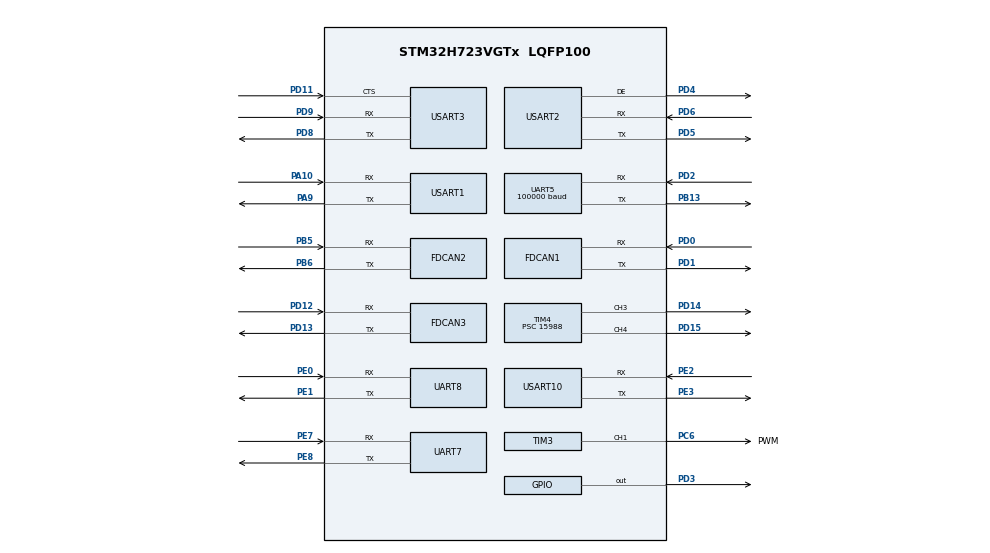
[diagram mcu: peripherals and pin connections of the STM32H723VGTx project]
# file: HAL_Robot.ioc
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Dma.Request0=TIM3_CH1
Dma.Request1=UART7_RX
Dma.Request10=USART1_TX
Dma.Request11=USART3_RX
Dma.Request12=USART3_TX
Dma.Request2=UART7_TX
Dma.Request3=UART8_RX
Dma.Request4=UART8_TX
Dma.Request5=USART10_RX
Dma.Request6=USART10_TX
Dma.Request7=UART5_RX
Dma.Request8=UART5_TX
Dma.Request9=USART1_RX
Dma.TIM3_CH1.0.Direction=DMA_MEMORY_TO_PERIPH
Dma.TIM3_CH1.0.EventEnable=DISABLE
Dma.TIM3_CH1.0.FIFOMode=DMA_FIFOMODE_DISABLE
Dma.TIM3_CH1.0.Instance=DMA1_Stream6
Dma.TIM3_CH1.0.MemDataAlignment=DMA_MDATAALIGN_HALFWORD
Dma.TIM3_CH1.0.MemInc=DMA_MINC_ENABLE
Dma.TIM3_CH1.0.Mode=DMA_NORMAL
Dma.TIM3_CH1.0.PeriphDataAlignment=DMA_PDATAALIGN_HALFWORD
Dma.TIM3_CH1.0.PeriphInc=DMA_PINC_DISABLE
Dma.TIM3_CH1.0.Polarity=HAL_DMAMUX_REQ_GEN_RISING
Dma.TIM3_CH1.0.Priority=DMA_PRIORITY_VERY_HIGH
Dma.TIM3_CH1.0.RequestNumber=1
Dma.TIM3_CH1.0.SignalID=NONE
Dma.TIM3_CH1.0.SyncEnable=DISABLE
Dma.TIM3_CH1.0.SyncPolarity=HAL_DMAMUX_SYNC_NO_EVENT
Dma.TIM3_CH1.0.SyncRequestNumber=1
Dma.TIM3_CH1.0.SyncSignalID=NONE
Dma.UART5_RX.7.Direction=DMA_PERIPH_TO_MEMORY
Dma.UART5_RX.7.EventEnable=DISABLE
Dma.UART5_RX.7.FIFOMode=DMA_FIFOMODE_DISABLE
Dma.UART5_RX.7.Instance=DMA2_Stream2
Dma.UART5_RX.7.MemDataAlignment=DMA_MDATAALIGN_BYTE
Dma.UART5_RX.7.MemInc=DMA_MINC_ENABLE
Dma.UART5_RX.7.Mode=DMA_CIRCULAR
Dma.UART5_RX.7.PeriphDataAlignment=DMA_PDATAALIGN_BYTE
Dma.UART5_RX.7.PeriphInc=DMA_PINC_DISABLE
Dma.UART5_RX.7.Polarity=HAL_DMAMUX_REQ_GEN_RISING
Dma.UART5_RX.7.Priority=DMA_PRIORITY_VERY_HIGH
Dma.UART5_RX.7.RequestNumber=1
Dma.UART5_RX.7.SignalID=NONE
Dma.UART5_RX.7.SyncEnable=DISABLE
Dma.UART5_RX.7.SyncPolarity=HAL_DMAMUX_SYNC_NO_EVENT
Dma.UART5_RX.7.SyncRequestNumber=1
Dma.UART5_RX.7.SyncSignalID=NONE
Dma.UART5_TX.8.Direction=DMA_MEMORY_TO_PERIPH
Dma.UART5_TX.8.EventEnable=DISABLE
Dma.UART5_TX.8.FIFOMode=DMA_FIFOMODE_DISABLE
Dma.UART5_TX.8.Instance=DMA2_Stream3
Dma.UART5_TX.8.MemDataAlignment=DMA_MDATAALIGN_BYTE
Dma.UART5_TX.8.MemInc=DMA_MINC_ENABLE
Dma.UART5_TX.8.Mode=DMA_CIRCULAR
Dma.UART5_TX.8.PeriphDataAlignment=DMA_PDATAALIGN_BYTE
Dma.UART5_TX.8.PeriphInc=DMA_PINC_DISABLE
Dma.UART5_TX.8.Polarity=HAL_DMAMUX_REQ_GEN_RISING
Dma.UART5_TX.8.Priority=DMA_PRIORITY_VERY_HIGH
Dma.UART5_TX.8.RequestNumber=1
Dma.UART5_TX.8.SignalID=NONE
Dma.UART5_TX.8.SyncEnable=DISABLE
Dma.UART5_TX.8.SyncPolarity=HAL_DMAMUX_SYNC_NO_EVENT
Dma.UART5_TX.8.SyncRequestNumber=1
Dma.UART5_TX.8.SyncSignalID=NONE
Dma.UART7_RX.1.Direction=DMA_PERIPH_TO_MEMORY
Dma.UART7_RX.1.EventEnable=DISABLE
Dma.UART7_RX.1.FIFOMode=DMA_FIFOMODE_DISABLE
Dma.UART7_RX.1.Instance=DMA1_Stream4
Dma.UART7_RX.1.MemDataAlignment=DMA_MDATAALIGN_BYTE
Dma.UART7_RX.1.MemInc=DMA_MINC_ENABLE
Dma.UART7_RX.1.Mode=DMA_CIRCULAR
Dma.UART7_RX.1.PeriphDataAlignment=DMA_PDATAALIGN_BYTE
Dma.UART7_RX.1.PeriphInc=DMA_PINC_DISABLE
Dma.UART7_RX.1.Polarity=HAL_DMAMUX_REQ_GEN_RISING
Dma.UART7_RX.1.Priority=DMA_PRIORITY_VERY_HIGH
Dma.UART7_RX.1.RequestNumber=1
Dma.UART7_RX.1.SignalID=NONE
Dma.UART7_RX.1.SyncEnable=DISABLE
Dma.UART7_RX.1.SyncPolarity=HAL_DMAMUX_SYNC_NO_EVENT
Dma.UART7_RX.1.SyncRequestNumber=1
Dma.UART7_RX.1.SyncSignalID=NONE
Dma.UART7_TX.2.Direction=DMA_MEMORY_TO_PERIPH
Dma.UART7_TX.2.EventEnable=DISABLE
Dma.UART7_TX.2.FIFOMode=DMA_FIFOMODE_DISABLE
Dma.UART7_TX.2.Instance=DMA1_Stream5
Dma.UART7_TX.2.MemDataAlignment=DMA_MDATAALIGN_BYTE
Dma.UART7_TX.2.MemInc=DMA_MINC_ENABLE
Dma.UART7_TX.2.Mode=DMA_NORMAL
Dma.UART7_TX.2.PeriphDataAlignment=DMA_PDATAALIGN_BYTE
Dma.UART7_TX.2.PeriphInc=DMA_PINC_DISABLE
Dma.UART7_TX.2.Polarity=HAL_DMAMUX_REQ_GEN_RISING
Dma.UART7_TX.2.Priority=DMA_PRIORITY_VERY_HIGH
Dma.UART7_TX.2.RequestNumber=1
Dma.UART7_TX.2.SignalID=NONE
Dma.UART7_TX.2.SyncEnable=DISABLE
Dma.UART7_TX.2.SyncPolarity=HAL_DMAMUX_SYNC_NO_EVENT
Dma.UART7_TX.2.SyncRequestNumber=1
Dma.UART7_TX.2.SyncSignalID=NONE
Dma.UART8_RX.3.Direction=DMA_PERIPH_TO_MEMORY
Dma.UART8_RX.3.EventEnable=DISABLE
Dma.UART8_RX.3.FIFOMode=DMA_FIFOMODE_DISABLE
Dma.UART8_RX.3.Instance=DMA1_Stream0
Dma.UART8_RX.3.MemDataAlignment=DMA_MDATAALIGN_BYTE
Dma.UART8_RX.3.MemInc=DMA_MINC_ENABLE
Dma.UART8_RX.3.Mode=DMA_CIRCULAR
Dma.UART8_RX.3.PeriphDataAlignment=DMA_PDATAALIGN_BYTE
Dma.UART8_RX.3.PeriphInc=DMA_PINC_DISABLE
Dma.UART8_RX.3.Polarity=HAL_DMAMUX_REQ_GEN_RISING
Dma.UART8_RX.3.Priority=DMA_PRIORITY_LOW
Dma.UART8_RX.3.RequestNumber=1
Dma.UART8_RX.3.SignalID=NONE
Dma.UART8_RX.3.SyncEnable=DISABLE
Dma.UART8_RX.3.SyncPolarity=HAL_DMAMUX_SYNC_NO_EVENT
Dma.UART8_RX.3.SyncRequestNumber=1
Dma.UART8_RX.3.SyncSignalID=NONE
Dma.UART8_TX.4.Direction=DMA_MEMORY_TO_PERIPH
Dma.UART8_TX.4.EventEnable=DISABLE
Dma.UART8_TX.4.FIFOMode=DMA_FIFOMODE_DISABLE
Dma.UART8_TX.4.Instance=DMA1_Stream3
Dma.UART8_TX.4.MemDataAlignment=DMA_MDATAALIGN_BYTE
Dma.UART8_TX.4.MemInc=DMA_MINC_ENABLE
Dma.UART8_TX.4.Mode=DMA_NORMAL
Dma.UART8_TX.4.PeriphDataAlignment=DMA_PDATAALIGN_BYTE
Dma.UART8_TX.4.PeriphInc=DMA_PINC_DISABLE
Dma.UART8_TX.4.Polarity=HAL_DMAMUX_REQ_GEN_RISING
Dma.UART8_TX.4.Priority=DMA_PRIORITY_LOW
Dma.UART8_TX.4.RequestNumber=1
Dma.UART8_TX.4.SignalID=NONE
Dma.UART8_TX.4.SyncEnable=DISABLE
Dma.UART8_TX.4.SyncPolarity=HAL_DMAMUX_SYNC_NO_EVENT
Dma.UART8_TX.4.SyncRequestNumber=1
Dma.UART8_TX.4.SyncSignalID=NONE
Dma.USART10_RX.5.Direction=DMA_PERIPH_TO_MEMORY
Dma.USART10_RX.5.EventEnable=DISABLE
Dma.USART10_RX.5.FIFOMode=DMA_FIFOMODE_DISABLE
Dma.USART10_RX.5.Instance=DMA1_Stream1
Dma.USART10_RX.5.MemDataAlignment=DMA_MDATAALIGN_BYTE
Dma.USART10_RX.5.MemInc=DMA_MINC_ENABLE
Dma.USART10_RX.5.Mode=DMA_CIRCULAR
Dma.USART10_RX.5.PeriphDataAlignment=DMA_PDATAALIGN_BYTE
Dma.USART10_RX.5.PeriphInc=DMA_PINC_DISABLE
Dma.USART10_RX.5.Polarity=HAL_DMAMUX_REQ_GEN_RISING
Dma.USART10_RX.5.Priority=DMA_PRIORITY_VERY_HIGH
Dma.USART10_RX.5.RequestNumber=1
Dma.USART10_RX.5.SignalID=NONE
Dma.USART10_RX.5.SyncEnable=DISABLE
Dma.USART10_RX.5.SyncPolarity=HAL_DMAMUX_SYNC_NO_EVENT
Dma.USART10_RX.5.SyncRequestNumber=1
Dma.USART10_RX.5.SyncSignalID=NONE
Dma.USART10_TX.6.Direction=DMA_MEMORY_TO_PERIPH
Dma.USART10_TX.6.EventEnable=DISABLE
Dma.USART10_TX.6.FIFOMode=DMA_FIFOMODE_DISABLE
Dma.USART10_TX.6.Instance=DMA1_Stream2
Dma.USART10_TX.6.MemDataAlignment=DMA_MDATAALIGN_BYTE
Dma.USART10_TX.6.MemInc=DMA_MINC_ENABLE
Dma.USART10_TX.6.Mode=DMA_CIRCULAR
Dma.USART10_TX.6.PeriphDataAlignment=DMA_PDATAALIGN_BYTE
Dma.USART10_TX.6.PeriphInc=DMA_PINC_DISABLE
Dma.USART10_TX.6.Polarity=HAL_DMAMUX_REQ_GEN_RISING
Dma.USART10_TX.6.Priority=DMA_PRIORITY_VERY_HIGH
Dma.USART10_TX.6.RequestNumber=1
Dma.USART10_TX.6.SignalID=NONE
Dma.USART10_TX.6.SyncEnable=DISABLE
Dma.USART10_TX.6.SyncPolarity=HAL_DMAMUX_SYNC_NO_EVENT
Dma.USART10_TX.6.SyncRequestNumber=1
Dma.USART10_TX.6.SyncSignalID=NONE
Dma.USART1_RX.9.Direction=DMA_PERIPH_TO_MEMORY
Dma.USART1_RX.9.EventEnable=DISABLE
Dma.USART1_RX.9.FIFOMode=DMA_FIFOMODE_DISABLE
Dma.USART1_RX.9.Instance=DMA1_Stream7
Dma.USART1_RX.9.MemDataAlignment=DMA_MDATAALIGN_BYTE
Dma.USART1_RX.9.MemInc=DMA_MINC_ENABLE
Dma.USART1_RX.9.Mode=DMA_CIRCULAR
Dma.USART1_RX.9.PeriphDataAlignment=DMA_PDATAALIGN_BYTE
Dma.USART1_RX.9.PeriphInc=DMA_PINC_DISABLE
Dma.USART1_RX.9.Polarity=HAL_DMAMUX_REQ_GEN_RISING
Dma.USART1_RX.9.Priority=DMA_PRIORITY_VERY_HIGH
Dma.USART1_RX.9.RequestNumber=1
Dma.USART1_RX.9.SignalID=NONE
Dma.USART1_RX.9.SyncEnable=DISABLE
Dma.USART1_RX.9.SyncPolarity=HAL_DMAMUX_SYNC_NO_EVENT
Dma.USART1_RX.9.SyncRequestNumber=1
Dma.USART1_RX.9.SyncSignalID=NONE
Dma.USART1_TX.10.Direction=DMA_MEMORY_TO_PERIPH
Dma.USART1_TX.10.EventEnable=DISABLE
Dma.USART1_TX.10.FIFOMode=DMA_FIFOMODE_DISABLE
Dma.USART1_TX.10.Instance=DMA2_Stream4
Dma.USART1_TX.10.MemDataAlignment=DMA_MDATAALIGN_BYTE
Dma.USART1_TX.10.MemInc=DMA_MINC_ENABLE
Dma.USART1_TX.10.Mode=DMA_CIRCULAR
Dma.USART1_TX.10.PeriphDataAlignment=DMA_PDATAALIGN_BYTE
Dma.USART1_TX.10.PeriphInc=DMA_PINC_DISABLE
Dma.USART1_TX.10.Polarity=HAL_DMAMUX_REQ_GEN_RISING
Dma.USART1_TX.10.Priority=DMA_PRIORITY_VERY_HIGH
Dma.USART1_TX.10.RequestNumber=1
Dma.USART1_TX.10.SignalID=NONE
Dma.USART1_TX.10.SyncEnable=DISABLE
Dma.USART1_TX.10.SyncPolarity=HAL_DMAMUX_SYNC_NO_EVENT
Dma.USART1_TX.10.SyncRequestNumber=1
Dma.USART1_TX.10.SyncSignalID=NONE
Dma.USART3_RX.11.Direction=DMA_PERIPH_TO_MEMORY
Dma.USART3_RX.11.EventEnable=DISABLE
Dma.USART3_RX.11.FIFOMode=DMA_FIFOMODE_DISABLE
Dma.USART3_RX.11.Instance=DMA2_Stream0
Dma.USART3_RX.11.MemDataAlignment=DMA_MDATAALIGN_BYTE
Dma.USART3_RX.11.MemInc=DMA_MINC_ENABLE
Dma.USART3_RX.11.Mode=DMA_NORMAL
Dma.USART3_RX.11.PeriphDataAlignment=DMA_PDATAALIGN_BYTE
Dma.USART3_RX.11.PeriphInc=DMA_PINC_DISABLE
Dma.USART3_RX.11.Polarity=HAL_DMAMUX_REQ_GEN_RISING
Dma.USART3_RX.11.Priority=DMA_PRIORITY_VERY_HIGH
Dma.USART3_RX.11.RequestNumber=1
Dma.USART3_RX.11.SignalID=NONE
Dma.USART3_RX.11.SyncEnable=DISABLE
Dma.USART3_RX.11.SyncPolarity=HAL_DMAMUX_SYNC_NO_EVENT
Dma.USART3_RX.11.SyncRequestNumber=1
Dma.USART3_RX.11.SyncSignalID=NONE
Dma.USART3_TX.12.Direction=DMA_MEMORY_TO_PERIPH
Dma.USART3_TX.12.EventEnable=DISABLE
Dma.USART3_TX.12.FIFOMode=DMA_FIFOMODE_DISABLE
Dma.USART3_TX.12.Instance=DMA2_Stream1
Dma.USART3_TX.12.MemDataAlignment=DMA_MDATAALIGN_BYTE
Dma.USART3_TX.12.MemInc=DMA_MINC_ENABLE
Dma.USART3_TX.12.Mode=DMA_NORMAL
Dma.USART3_TX.12.PeriphDataAlignment=DMA_PDATAALIGN_BYTE
Dma.USART3_TX.12.PeriphInc=DMA_PINC_DISABLE
Dma.USART3_TX.12.Polarity=HAL_DMAMUX_REQ_GEN_RISING
Dma.USART3_TX.12.Priority=DMA_PRIORITY_VERY_HIGH
Dma.USART3_TX.12.RequestNumber=1
Dma.USART3_TX.12.SignalID=NONE
Dma.USART3_TX.12.SyncEnable=DISABLE
Dma.USART3_TX.12.SyncPolarity=HAL_DMAMUX_SYNC_NO_EVENT
Dma.USART3_TX.12.SyncRequestNumber=1
Dma.USART3_TX.12.SyncSignalID=NONE
FDCAN1.CalculateBaudRateNominal=1000000
FDCAN1.CalculateTimeBitNominal=1000
FDCAN1.CalculateTimeQuantumNominal=100.0
FDCAN1.MessageRAMOffset=180
FDCAN1.NominalPrescaler=10
FDCAN1.NominalTimeSeg1=7
FDCAN1.NominalTimeSeg2=2
FDCAN1.RxFifo0ElmtsNbr=16
FDCAN1.TxFifoQueueElmtsNbr=8
FDCAN2.CalculateBaudRateNominal=1000000
FDCAN2.CalculateTimeBitNominal=1000
FDCAN2.CalculateTimeQuantumNominal=100.0
FDCAN2.MessageRAMOffset=180
FDCAN2.NominalPrescaler=10
FDCAN2.NominalTimeSeg1=7
FDCAN2.NominalTimeSeg2=2
FDCAN2.RxFifo0ElmtsNbr=16
FDCAN2.TxFifoQueueElmtsNbr=8
FDCAN3.CalculateBaudRateNominal=1000000
FDCAN3.CalculateTimeBitNominal=1000
FDCAN3.CalculateTimeQuantumNominal=100.0
FDCAN3.MessageRAMOffset=450
FDCAN3.NominalPrescaler=10
FDCAN3.NominalTimeSeg1=7
FDCAN3.NominalTimeSeg2=2
FDCAN3.RxFifo0ElmtsNbr=16
FDCAN3.TxFifoQueueElmtsNbr=8
FREERTOS.Tasks01=defaultTask,24,128,StartDefaultTask,Default,NULL,Dynamic,NULL,NULL;RTOSsystem_task,10,128,RTOSsystem_Task,As external,NULL,Dynamic,NULL,NULL;Gimbal_task256,13,512,Gimbal_Task,As external,NULL,Dynamic,NULL,NULL;Guard_task,14,128,Guard_Task,As external,NULL,Dynamic,NULL,NULL;Correspond_task,12,512,Correspond_Task,As external,NULL,Dynamic,NULL,NULL;Message_task,13,128,Message_Task,As external,NULL,Dynamic,NULL,NULL;CAN1_Rx_task,15,128,CAN1_Rx_Task,As external,NULL,Dynamic,NULL,NULL;CAN2_Rx_task,15,128,CAN2_Rx_Task,As external,NULL,Dynamic,NULL,NULL;Serial_Rx_task,15,128,Serial_Rx_Task,As external,NULL,Dynamic,NULL,NULL;DR16_Rx_task,15,128,DR16_Rx_Task,As external,NULL,Dynamic,NULL,NULL;CAN3_Rx_task,15,128,CAN3_Rx_Task,As external,NULL,Dynamic,NULL,NULL;Chassis_task,13,512,Chassis_Task,As external,NULL,Dynamic,NULL,NULL;UIDraw_task,11,256,UIDraw_Task,As external,NULL,Dynamic,NULL,NULL;Referee_Rx_task,15,128,Referee_Rx_Task,As external,NULL,Dynamic,NULL,NULL
Mcu.Family=STM32H7
Mcu.Name=STM32H723VGTx
Mcu.Package=LQFP100
NVIC.DMA1_Stream0_IRQn=true\:5\:0\:false\:false\:true\:true\:false\:true\:true
NVIC.DMA1_Stream1_IRQn=true\:5\:0\:false\:false\:true\:false\:false\:true\:true
NVIC.DMA1_Stream2_IRQn=true\:5\:0\:false\:false\:true\:true\:false\:true\:true
NVIC.DMA1_Stream3_IRQn=true\:5\:0\:false\:false\:true\:true\:false\:true\:true
NVIC.DMA1_Stream4_IRQn=true\:5\:0\:false\:false\:true\:true\:false\:true\:true
NVIC.DMA1_Stream5_IRQn=true\:5\:0\:false\:false\:true\:true\:false\:true\:true
NVIC.DMA1_Stream6_IRQn=true\:5\:0\:false\:false\:true\:true\:false\:true\:true
NVIC.DMA1_Stream7_IRQn=true\:5\:0\:false\:false\:true\:true\:false\:true\:true
NVIC.DMA2_Stream0_IRQn=true\:5\:0\:false\:false\:true\:true\:false\:true\:true
NVIC.DMA2_Stream1_IRQn=true\:5\:0\:false\:false\:true\:true\:false\:true\:true
NVIC.DMA2_Stream2_IRQn=true\:5\:0\:false\:false\:true\:false\:false\:true\:true
NVIC.DMA2_Stream3_IRQn=true\:5\:0\:false\:false\:true\:false\:false\:true\:true
NVIC.DMA2_Stream4_IRQn=true\:5\:0\:false\:false\:true\:true\:false\:true\:true
NVIC.FDCAN1_IT0_IRQn=true\:5\:0\:false\:false\:true\:true\:true\:true\:true
NVIC.FDCAN2_IT0_IRQn=true\:5\:0\:false\:false\:true\:true\:true\:true\:true
NVIC.FDCAN3_IT0_IRQn=true\:5\:0\:false\:false\:true\:true\:true\:true\:true
NVIC.PriorityGroup=NVIC_PRIORITYGROUP_4
NVIC.TIM1_UP_IRQn=true\:15\:0\:false\:false\:true\:false\:false\:true\:true
NVIC.TimeBase=TIM1_UP_IRQn
NVIC.TimeBaseIP=TIM1
NVIC.UART5_IRQn=true\:5\:0\:false\:false\:true\:true\:true\:true\:true
NVIC.UART7_IRQn=true\:5\:0\:true\:false\:true\:true\:true\:true\:true
NVIC.UART8_IRQn=true\:6\:0\:true\:false\:true\:true\:true\:true\:true
NVIC.USART10_IRQn=true\:5\:0\:false\:false\:true\:true\:true\:true\:true
NVIC.USART1_IRQn=true\:5\:0\:false\:false\:true\:true\:true\:true\:true
NVIC.USART3_IRQn=true\:5\:0\:false\:false\:true\:true\:true\:true\:true
PA10.Mode=Asynchronous
PA10.Signal=USART1_RX
PA13(JTMS/SWDIO).Mode=Serial_Wire
PA13(JTMS/SWDIO).Signal=DEBUG_JTMS-SWDIO
PA14(JTCK/SWCLK).Mode=Serial_Wire
PA14(JTCK/SWCLK).Signal=DEBUG_JTCK-SWCLK
PA9.Mode=Asynchronous
PA9.Signal=USART1_TX
PB1.Signal=S_TIM3_CH4
PB13.GPIO_Speed=GPIO_SPEED_FREQ_VERY_HIGH
PB13.Mode=Asynchronous
PB13.Signal=UART5_TX
PB14.Signal=UART4_DE
PB5.GPIO_Speed=GPIO_SPEED_FREQ_VERY_HIGH
PB5.Mode=FDCAN_Activate
PB5.Signal=FDCAN2_RX
PB6.GPIO_Speed=GPIO_SPEED_FREQ_VERY_HIGH
PB6.Mode=FDCAN_Activate
PB6.Signal=FDCAN2_TX
PC6.GPIO_Label=PWM
PC6.GPIO_PuPd=GPIO_PULLUP
PC6.GPIO_Speed=GPIO_SPEED_FREQ_VERY_HIGH
PC6.Signal=S_TIM3_CH1
PD0.GPIO_Speed=GPIO_SPEED_FREQ_VERY_HIGH
PD0.Mode=FDCAN_Activate
PD0.Signal=FDCAN1_RX
PD1.GPIO_Speed=GPIO_SPEED_FREQ_VERY_HIGH
PD1.Mode=FDCAN_Activate
PD1.Signal=FDCAN1_TX
PD11.Mode=CTS_Only
PD11.Signal=USART3_CTS
PD12.GPIO_Speed=GPIO_SPEED_FREQ_VERY_HIGH
PD12.Mode=FDCAN_Activate
PD12.Signal=FDCAN3_RX
PD13.GPIO_Speed=GPIO_SPEED_FREQ_VERY_HIGH
PD13.Mode=FDCAN_Activate
PD13.Signal=FDCAN3_TX
PD14.GPIO_ModeDefaultPP=GPIO_MODE_AF_PP
PD14.GPIO_PuPd=GPIO_NOPULL
PD14.GPIO_Speed=GPIO_SPEED_FREQ_HIGH
PD14.Signal=S_TIM4_CH3
PD15.Signal=S_TIM4_CH4
PD2.GPIO_Speed=GPIO_SPEED_FREQ_VERY_HIGH
PD2.Mode=Asynchronous
PD2.Signal=UART5_RX
PD3.Signal=GPIO_Output
PD4.Mode=Hardware Flow Control (RS485)
PD4.Signal=USART2_DE
PD5.Mode=Asynchronous
PD5.Signal=USART2_TX
PD6.Mode=Asynchronous
PD6.Signal=USART2_RX
PD8.Mode=Asynchronous
PD8.Signal=USART3_TX
PD9.Mode=Asynchronous
PD9.Signal=USART3_RX
PE0.GPIO_Speed=GPIO_SPEED_FREQ_VERY_HIGH
PE0.Mode=Asynchronous
PE0.Signal=UART8_RX
PE1.GPIO_Speed=GPIO_SPEED_FREQ_VERY_HIGH
PE1.Mode=Asynchronous
PE1.Signal=UART8_TX
PE2.GPIO_Speed=GPIO_SPEED_FREQ_VERY_HIGH
PE2.Mode=Asynchronous
PE2.Signal=USART10_RX
PE3.GPIO_Speed=GPIO_SPEED_FREQ_VERY_HIGH
PE3.Mode=Asynchronous
PE3.Signal=USART10_TX
PE7.GPIO_Speed=GPIO_SPEED_FREQ_VERY_HIGH
PE7.Mode=Asynchronous
PE7.Signal=UART7_RX
PE8.GPIO_Speed=GPIO_SPEED_FREQ_VERY_HIGH
PE8.Mode=Asynchronous
PE8.Signal=UART7_TX
PH0-OSC_IN.Mode=HSE-External-Oscillator
PH0-OSC_IN.Signal=RCC_OSC_IN
PH1-OSC_OUT.Mode=HSE-External-Oscillator
PH1-OSC_OUT.Signal=RCC_OSC_OUT
ProjectManager.HeapSize=0x1000
ProjectManager.StackSize=0x400
ProjectManager.TargetToolchain=MDK-ARM V5.32
RCC.ADCFreq_Value=100000000
RCC.APB1Freq_Value=137500000
RCC.APB2Freq_Value=137500000
RCC.APB3Freq_Value=137500000
RCC.APB4Freq_Value=137500000
RCC.CortexFreq_Value=550000000
RCC.D1PPRE=RCC_APB3_DIV2
RCC.D2PPRE1=RCC_APB1_DIV2
RCC.D2PPRE2=RCC_APB2_DIV2
RCC.D3PPRE=RCC_APB4_DIV2
RCC.DIVM1=3
RCC.DIVM2=3
RCC.DIVN1=68
RCC.DIVN2=25
RCC.DIVN3=403
RCC.DIVP1=1
RCC.DIVQ3=6
RCC.FDCANCLockSelection=RCC_FDCANCLKSOURCE_PLL2
RCC.HCLKFreq_Value=275000000
RCC.HPRE=RCC_HCLK_DIV2
RCC.HSE_VALUE=24000000
RCC.PLL2FRACN=0
RCC.PLL3FRACN=0
RCC.PLLFRACN=6144
RCC.PLLSourceVirtual=RCC_PLLSOURCE_HSE
RCC.SYSCLKFreq_VALUE=550000000
RCC.SYSCLKSource=RCC_SYSCLKSOURCE_PLLCLK
RCC.USBFreq_Value=275000000
SH.S_TIM3_CH1.0=TIM3_CH1,PWM Generation1 CH1
SH.S_TIM3_CH4.0=TIM3_CH4
SH.S_TIM4_CH3.0=TIM4_CH3,PWM Generation3 CH3
SH.S_TIM4_CH4.0=TIM4_CH4,PWM Generation4 CH4
TIM2.Period=209
TIM2.Prescaler=0
TIM3.Channel-PWM\ Generation1\ CH1=TIM_CHANNEL_1
TIM3.Period=343
TIM3.Prescaler=0
TIM4.Channel-PWM\ Generation3\ CH3=TIM_CHANNEL_3
TIM4.Channel-PWM\ Generation4\ CH4=TIM_CHANNEL_4
TIM4.Period=343
TIM4.Prescaler=15988
UART5.BaudRate=100000
USART1.VirtualMode-Asynchronous=VM_ASYNC
USART10.VirtualMode=VM_ASYNC
USART2.VirtualMode-Asynchronous=VM_ASYNC
USART2.VirtualMode-Hardware\ Flow\ Control\ (RS485)=VM_ASYNC
USART3.VirtualMode-Asynchronous=VM_ASYNC
VP_FREERTOS_VS_CMSIS_V2.Mode=CMSIS_V2
VP_MEMORYMAP_VS_MEMORYMAP.Mode=CurAppReg
VP_SYS_VS_tim1.Mode=TIM1
VP_TIM2_VS_ClockSourceINT.Mode=Internal
VP_TIM3_VS_ClockSourceINT.Mode=Internal
VP_TIM4_VS_ClockSourceINT.Mode=Internal
board=custom

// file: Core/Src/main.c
/* USER CODE BEGIN Header */
/**
 ******************************************************************************
 * @file           : main.c
 * @brief          : Main program body
 ******************************************************************************
 * @attention
 *
 * Copyright (c) 2023 STMicroelectronics.
 * All rights reserved.
 *
 * This software is licensed under terms that can be found in the LICENSE file
 * in the root directory of this software component.
 * If no LICENSE file comes with this software, it is provided AS-IS.
 *
 ******************************************************************************
 */
/* USER CODE END Header */
#include "main.h"
#include "cmsis_os.h"
#include "dma.h"
#include "fdcan.h"
#include "memorymap.h"
#include "tim.h"
#include "usart.h"
#include "gpio.h"

/* USER CODE BEGIN Includes */
#include "protocol_dbus.h"
#include "drivers_dma.h"
#include "bsp_dwt.h"
/* USER CODE END Includes */

void SystemClock_Config(void);
void PeriphCommonClock_Config(void);
void MX_FREERTOS_Init(void);

/* USER CODE BEGIN 0 */

//void SoftWareInit(void)
//{
//	HAL_TIM_PWM_Start(&htim4,TIM_CHANNEL_3); //����PWM��Ӧ��ͨ��
//	HAL_TIM_PWM_Start(&htim4,TIM_CHANNEL_4); //����PWM��Ӧ��ͨ��
//
//	HAL_GPIO_WritePin(GPIOD,GPIO_PIN_3,GPIO_PIN_SET);
//
//}

/* USER CODE END 0 */

int main(void)
{

  /* MCU Configuration--------------------------------------------------------*/

  /* Reset of all peripherals, Initializes the Flash interface and the Systick. */
  HAL_Init();

  /* Configure the system clock */
  SystemClock_Config();

  /* Configure the peripherals common clocks */
  PeriphCommonClock_Config();

  /* Initialize all configured peripherals */
  MX_GPIO_Init();
  MX_DMA_Init();
  MX_TIM2_Init();
  MX_FDCAN1_Init();
  MX_FDCAN2_Init();
  MX_FDCAN3_Init();
  MX_TIM3_Init();
  MX_UART7_Init();
  MX_UART8_Init();
  MX_TIM4_Init();
  MX_USART10_UART_Init();
  MX_UART5_Init();
  MX_USART1_UART_Init();
  MX_USART3_UART_Init();
  MX_USART2_UART_Init();
  /* USER CODE BEGIN 2 */
  //SoftWareInit();
	DWT_Init(550);
  /* USER CODE END 2 */

  /* Init scheduler */
  osKernelInitialize();

  /* Call init function for freertos objects (in cmsis_os2.c) */
  MX_FREERTOS_Init();

  /* Start scheduler */
  osKernelStart();

  /* We should never get here as control is now taken by the scheduler */

  /* Infinite loop */
  while (1)
  {

  }
}

void SystemClock_Config(void)
{
  RCC_OscInitTypeDef RCC_OscInitStruct = {0};
  RCC_ClkInitTypeDef RCC_ClkInitStruct = {0};

  /** Supply configuration update enable
  */
  HAL_PWREx_ConfigSupply(PWR_LDO_SUPPLY);

  /** Configure the main internal regulator output voltage
  */
  __HAL_PWR_VOLTAGESCALING_CONFIG(PWR_REGULATOR_VOLTAGE_SCALE0);

  while(!__HAL_PWR_GET_FLAG(PWR_FLAG_VOSRDY)) {}

  /** Initializes the RCC Oscillators according to the specified parameters
  * in the RCC_OscInitTypeDef structure.
  */
  RCC_OscInitStruct.OscillatorType = RCC_OSCILLATORTYPE_HSE;
  RCC_OscInitStruct.HSEState = RCC_HSE_ON;
  RCC_OscInitStruct.PLL.PLLState = RCC_PLL_ON;
  RCC_OscInitStruct.PLL.PLLSource = RCC_PLLSOURCE_HSE;
  RCC_OscInitStruct.PLL.PLLM = 3;
  RCC_OscInitStruct.PLL.PLLN = 68;
  RCC_OscInitStruct.PLL.PLLP = 1;
  RCC_OscInitStruct.PLL.PLLQ = 2;
  RCC_OscInitStruct.PLL.PLLR = 2;
  RCC_OscInitStruct.PLL.PLLRGE = RCC_PLL1VCIRANGE_3;
  RCC_OscInitStruct.PLL.PLLVCOSEL = RCC_PLL1VCOWIDE;
  RCC_OscInitStruct.PLL.PLLFRACN = 6144;
  if (HAL_RCC_OscConfig(&RCC_OscInitStruct) != HAL_OK)
  {
    Error_Handler();
  }

  /** Initializes the CPU, AHB and APB buses clocks
  */
  RCC_ClkInitStruct.ClockType = RCC_CLOCKTYPE_HCLK|RCC_CLOCKTYPE_SYSCLK
                              |RCC_CLOCKTYPE_PCLK1|RCC_CLOCKTYPE_PCLK2
                              |RCC_CLOCKTYPE_D3PCLK1|RCC_CLOCKTYPE_D1PCLK1;
  RCC_ClkInitStruct.SYSCLKSource = RCC_SYSCLKSOURCE_PLLCLK;
  RCC_ClkInitStruct.SYSCLKDivider = RCC_SYSCLK_DIV1;
  RCC_ClkInitStruct.AHBCLKDivider = RCC_HCLK_DIV2;
  RCC_ClkInitStruct.APB3CLKDivider = RCC_APB3_DIV2;
  RCC_ClkInitStruct.APB1CLKDivider = RCC_APB1_DIV2;
  RCC_ClkInitStruct.APB2CLKDivider = RCC_APB2_DIV2;
  RCC_ClkInitStruct.APB4CLKDivider = RCC_APB4_DIV2;

  if (HAL_RCC_ClockConfig(&RCC_ClkInitStruct, FLASH_LATENCY_3) != HAL_OK)
  {
    Error_Handler();
  }
}

void PeriphCommonClock_Config(void)
{
  RCC_PeriphCLKInitTypeDef PeriphClkInitStruct = {0};

  /** Initializes the peripherals clock
  */
  PeriphClkInitStruct.PeriphClockSelection = RCC_PERIPHCLK_FDCAN;
  PeriphClkInitStruct.PLL2.PLL2M = 3;
  PeriphClkInitStruct.PLL2.PLL2N = 25;
  PeriphClkInitStruct.PLL2.PLL2P = 2;
  PeriphClkInitStruct.PLL2.PLL2Q = 2;
  PeriphClkInitStruct.PLL2.PLL2R = 2;
  PeriphClkInitStruct.PLL2.PLL2RGE = RCC_PLL2VCIRANGE_3;
  PeriphClkInitStruct.PLL2.PLL2VCOSEL = RCC_PLL2VCOWIDE;
  PeriphClkInitStruct.PLL2.PLL2FRACN = 0;
  PeriphClkInitStruct.FdcanClockSelection = RCC_FDCANCLKSOURCE_PLL2;
  if (HAL_RCCEx_PeriphCLKConfig(&PeriphClkInitStruct) != HAL_OK)
  {
    Error_Handler();
  }
}

void HAL_TIM_PeriodElapsedCallback(TIM_HandleTypeDef *htim)
{
  if (htim->Instance == TIM1)
  {
    HAL_IncTick();
  }
}

void Error_Handler(void)
{
  __disable_irq();
  while (1)
  {
  }
}
